# PY32F001xx register map
Vendor: Puya; Series: PY32F0; File version: 1.0.0
CPU: CM0+ r0p1, little endian, no MPU, no FPU, 4 interrupt priority bits
Registers are 32-bit, read-write, reset 0x0 unless marked. A register's access mark holds for its fields unless they carry their own. Offsets are from the block's base; [hi:lo] are bit positions; {n}, {i} and the like mark numbered series.

## GPIOB — General-purpose I/Os
Base 0x50000400
Same registers: GPIOC 0x50000800
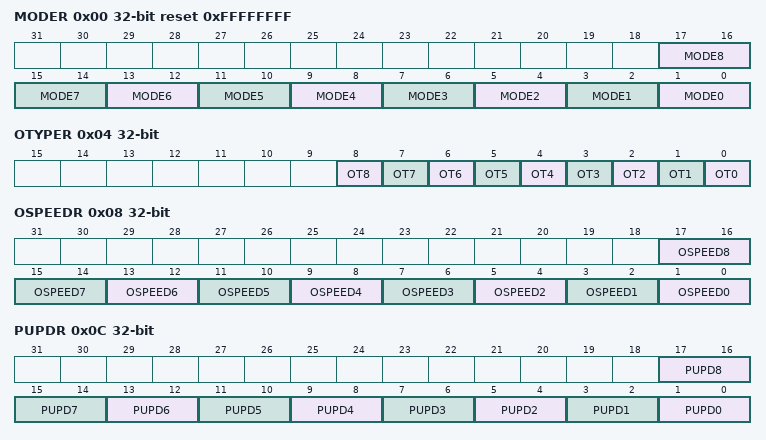
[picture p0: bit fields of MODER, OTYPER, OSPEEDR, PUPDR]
0x00 MODER reset 0xFFFFFFFF — GPIO port mode register
  [2n+1:2n] MODE{n} (n=0..8) — Port x configuration bits (y = 0..15)
0x04 OTYPER — GPIO port output type register
  [n] OT{n} (n=0..8) — Port x configuration bits (y = 0..15)
0x08 OSPEEDR — GPIO port output speed register
  [2n+1:2n] OSPEED{n} (n=0..8) — Port x configuration bits (y = 0..15)
0x0C PUPDR — GPIO port pull-up/pull-down register
  [2n+1:2n] PUPD{n} (n=0..8) — Port x configuration bits (y = 0..15)
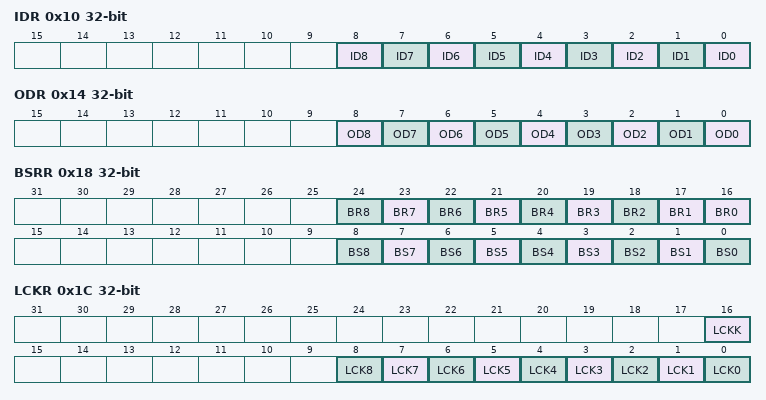
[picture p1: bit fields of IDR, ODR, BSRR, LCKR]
0x10 IDR ro — GPIO port input data register
  [n] ID{n} (n=0..8) — Port input data (y = 0..15)
0x14 ODR — GPIO port output data register
  [n] OD{n} (n=0..8) — Port output data (y = 0..15)
0x18 BSRR wo — GPIO port bit set/reset register
  [n+16] BR{n} (n=1..8) — Port x reset bit y (y = 0..15)
  [16] BR0 — Port x set bit y (y= 0..15)
  [n] BS{n} (n=0..8) — Port x set bit y (y= 0..15)
0x1C LCKR — GPIO port configuration lock register
  [16] LCKK — Port x lock bit y (y= 0..15)
  [n] LCK{n} (n=0..8) — Port x lock bit y (y= 0..15)
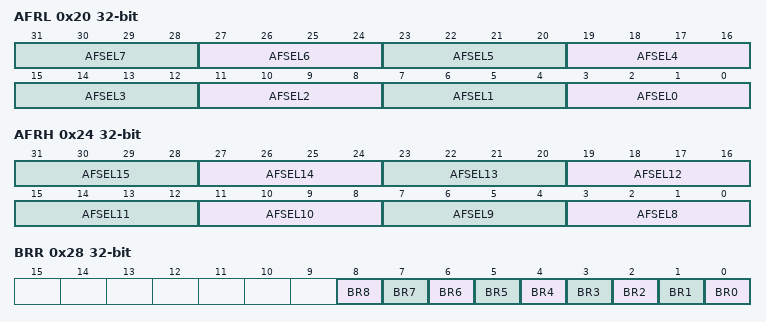
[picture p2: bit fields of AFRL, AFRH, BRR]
0x20 AFRL — GPIO alternate function low register
  [4n+3:4n] AFSEL{n} (n=0..7) — Alternate function selection for port x bit y (y = 0..7)
0x24 AFRH — GPIO alternate function high register
  [4n-29:4n-32] AFSEL{n} (n=8..15) — Alternate function selection for port x bit y (y = 8..15)
0x28 BRR wo — port bit reset register
  [n] BR{n} (n=0..8) — Port Reset bit

## IWDG — Independent watchdog
Base 0x40003000
0x00 KR wo — Key register (IWDG_KR)
  [15:0] KEY — Key value
0x04 PR — Prescaler register (IWDG_PR)
  [2:0] PR — Prescaler divider
0x08 RLR reset 0xFFF — Reload register (IWDG_RLR)
  [11:0] RL — Watchdog counter reload value
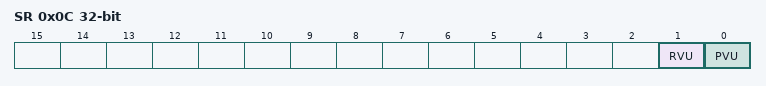
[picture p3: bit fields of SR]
0x0C SR ro — Status register (IWDG_SR)
  [1] RVU — Watchdog counter reload value update
  [0] PVU — Watchdog prescaler value update

## LPTIM1 — Low power timer
Base 0x40007C00
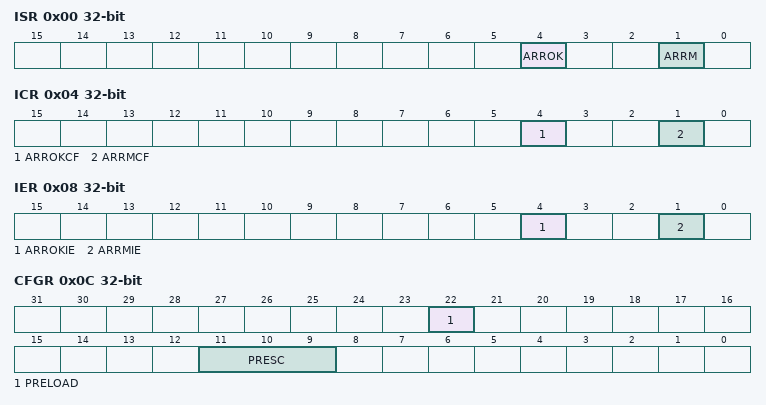
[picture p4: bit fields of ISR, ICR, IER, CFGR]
0x00 ISR ro — Interrupt and Status Register
  [4] ARROK — Autoreload match update OK
  [1] ARRM — Autoreload match
0x04 ICR wo — Interrupt Clear Register
  [4] ARROKCF — Autoreload match update OK Clear Flag
  [1] ARRMCF — Autoreload match Clear Flag
0x08 IER — Interrupt Enable Register
  [4] ARROKIE — Autoreload match update OK Interrupt Enable
  [1] ARRMIE — Autoreload matchInterrupt Enable
0x0C CFGR — Configuration Register
  [22] PRELOAD — Registers update mode
  [11:9] PRESC — Clock prescaler
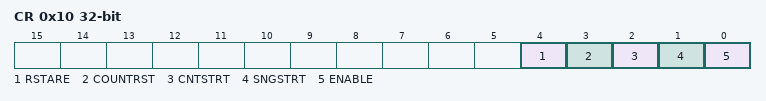
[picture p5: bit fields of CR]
0x10 CR — Control Register
  [4] RSTARE — Reset after read enable
  [3] COUNTRST — LPTIM counter reset
  [2] CNTSTRT
  [1] SNGSTRT — LPTIM start in single mode
  [0] ENABLE — LPTIM Enable
0x18 ARR reset 0x1 — Autoreload Register
  [15:0] ARR — Auto reload value
0x1C CNT ro — Counter Register
  [15:0] CNT — Counter value

## PWR — Power control
Base 0x40007000
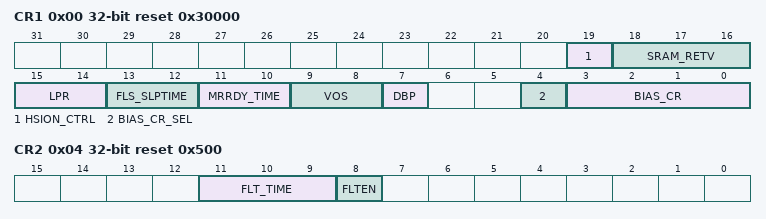
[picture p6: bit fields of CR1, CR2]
0x00 CR1 reset 0x30000 — Power control register 1
  [19] HSION_CTRL — HSI open time control
  [18:16] SRAM_RETV — SRAM retention voltage control
  [15:14] LPR — Low-power run
  [13:12] FLS_SLPTIME — Flash wait time after wakeup from the stop mode
  [11:10] MRRDY_TIME — Time selection wakeup from LP to VR
  [9:8] VOS — Voltage scaling range selection
  [7] DBP — Disable backup domain write protection
  [4] BIAS_CR_SEL — MR Bias current selection
  [3:0] BIAS_CR — MR Bias current
0x04 CR2 reset 0x500 — Power control register 2
  [11:9] FLT_TIME — Digital filter time configuration
  [8] FLTEN — Digital filter enable

## SYSCFG — System configuration controller
Base 0x40010000
0x00 CFGR1 — SYSCFG configuration register 1
  [1:0] MEM_MODE — Memory mapping selection bits
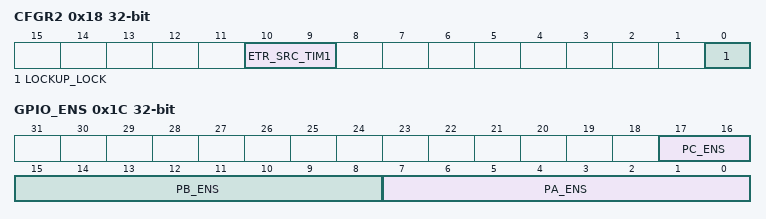
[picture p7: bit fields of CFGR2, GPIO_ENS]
0x18 CFGR2 — SYSCFG configuration register 2
  [10:9] ETR_SRC_TIM1 — TIM1 ETR source selection
  [0] LOCKUP_LOCK — Cortex-M0+ LOCKUP bit enable bit
0x1C GPIO_ENS
  [17:16] PC_ENS, [15:8] PB_ENS, [7:0] PA_ENS

## TIM1 — Advanced timer
Base 0x40012C00
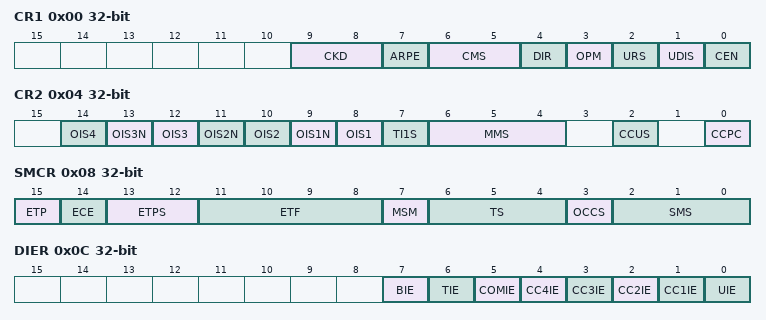
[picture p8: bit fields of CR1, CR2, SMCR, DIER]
0x00 CR1
  [9:8] CKD, [7] ARPE, [6:5] CMS, [4] DIR, [3] OPM, [2] URS, [1] UDIS, [0] CEN
0x04 CR2 (reset mask 0xF8)
  [2n+6] OIS{n} (n=1..4), [13] OIS3N, [11] OIS2N, [9] OIS1N, [7] TI1S, [6:4] MMS, [2] CCUS, [0] CCPC
0x08 SMCR (reset mask 0xFFF7)
  [15] ETP, [14] ECE, [13:12] ETPS, [11:8] ETF, [7] MSM, [6:4] TS, [3] OCCS, [2:0] SMS
0x0C DIER (reset mask 0x5F5F)
  [7] BIE, [6] TIE, [5] COMIE, [n] CC{n}IE (n=1..4), [0] UIE
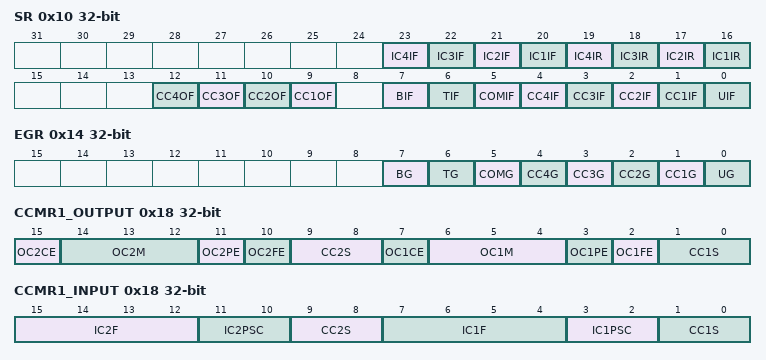
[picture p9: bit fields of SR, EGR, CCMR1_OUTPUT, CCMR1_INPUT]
0x10 SR (reset mask 0x1E5F)
  [23] IC4IF — desc IC3IF
  [22] IC3IF
  [21] IC2IF
  [20] IC1IF
  [19] IC4IR — desc IC3IR
  [18] IC3IR
  [17] IC2IR
  [16] IC1IR
  [n+8] CC{n}OF (n=1..4)
  [7] BIF
  [6] TIF
  [5] COMIF
  [n] CC{n}IF (n=1..4)
  [0] UIF
0x14 EGR wo (reset mask 0x5F)
  [7] BG
  [6] TG
  [5] COMG
  [4] CC4G
  [3] CC3G
  [2] CC2G
  [1] CC1G — Capture/Compare 1 Generation
  [0] UG
0x18 CCMR1_OUTPUT
  [15] OC2CE, [14:12] OC2M, [11] OC2PE, [10] OC2FE, [9:8] CC2S, [7] OC1CE, [6:4] OC1M, [3] OC1PE, [2] OC1FE, [1:0] CC1S
0x18 CCMR1_INPUT (alternate view of CCMR1_OUTPUT)
  [15:12] IC2F, [11:10] IC2PSC, [9:8] CC2S, [7:4] IC1F, [3:2] IC1PSC, [1:0] CC1S
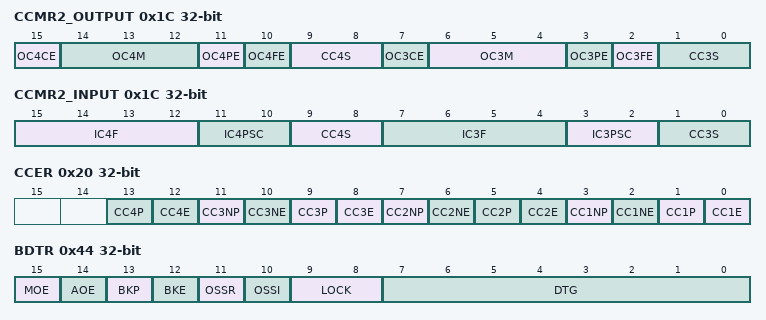
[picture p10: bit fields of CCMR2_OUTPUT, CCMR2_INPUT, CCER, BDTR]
0x1C CCMR2_OUTPUT
  [15] OC4CE, [14:12] OC4M, [11] OC4PE, [10] OC4FE, [9:8] CC4S, [7] OC3CE, [6:4] OC3M, [3] OC3PE, [2] OC3FE, [1:0] CC3S
0x1C CCMR2_INPUT (alternate view of CCMR2_OUTPUT)
  [15:12] IC4F, [11:10] IC4PSC, [9:8] CC4S, [7:4] IC3F, [3:2] IC3PSC, [1:0] CC3S
0x20 CCER (reset mask 0x3333)
  [4n-3] CC{n}P (n=1..4), [4n-4] CC{n}E (n=1..4), [11] CC3NP, [10] CC3NE, [7] CC2NP, [6] CC2NE, [3] CC1NP, [2] CC1NE
0x24 CNT
  [15:0] CNT
0x28 PSC
  [15:0] PSC
0x2C ARR reset 0xFFFF
  [15:0] ARR
0x30 RCR reset 0xFFFF
  [7:0] REP
{0x30+4i} CCR{i} (i=1..4)
  [15:0] CCR{i}
0x44 BDTR
  [15] MOE, [14] AOE, [13] BKP, [12] BKE, [11] OSSR, [10] OSSI, [9:8] LOCK, [7:0] DTG

## TIM14 — General purpose timer
Base 0x40002000
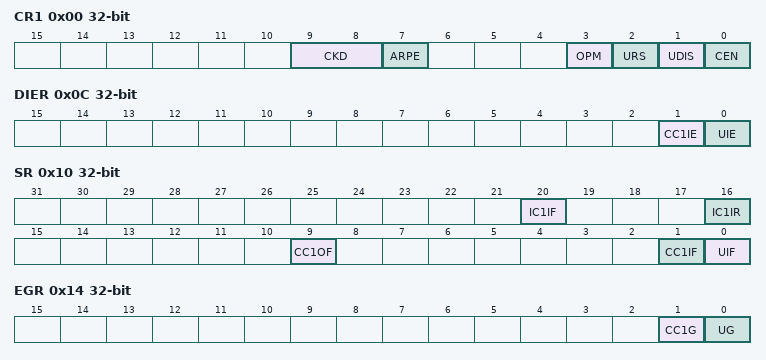
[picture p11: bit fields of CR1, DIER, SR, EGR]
0x00 CR1
  [9:8] CKD, [7] ARPE, [3] OPM, [2] URS, [1] UDIS, [0] CEN
0x0C DIER
  [1] CC1IE, [0] UIE
0x10 SR (reset mask 0x1E5F)
  [20] IC1IF, [16] IC1IR, [9] CC1OF, [1] CC1IF, [0] UIF
0x14 EGR wo
  [1] CC1G — Capture/Compare 1 Generation
  [0] UG
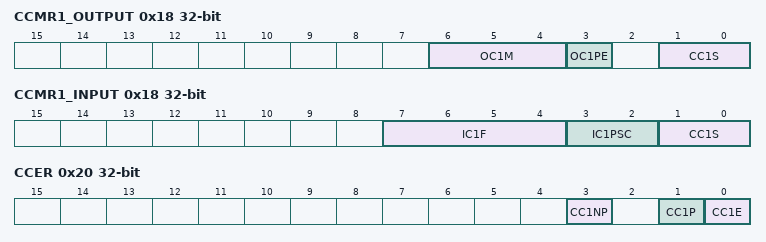
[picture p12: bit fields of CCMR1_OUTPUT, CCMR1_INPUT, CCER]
0x18 CCMR1_OUTPUT
  [6:4] OC1M, [3] OC1PE, [1:0] CC1S
0x18 CCMR1_INPUT (alternate view of CCMR1_OUTPUT)
  [7:4] IC1F, [3:2] IC1PSC, [1:0] CC1S
0x20 CCER (reset mask 0x3333)
  [3] CC1NP, [1] CC1P, [0] CC1E
0x24 CNT
  [15:0] CNT
0x28 PSC
  [15:0] PSC
0x2C ARR reset 0xFFFF
  [15:0] ARR
0x34 CCR1
  [15:0] CCR1
0x50 OR
  [1:0] TI1_RMP
